# GD32F3x0 register map
File version: 1.0
CPU: CM4 r2p1, little endian, MPU, no FPU, 4 interrupt priority bits
Registers are 32-bit, read-write, reset 0x0 unless marked. A register's access mark holds for its fields unless they carry their own. Offsets are from the block's base; [hi:lo] are bit positions; {n}, {i} and the like mark numbered series.

## EXTI — External interrupt/event controller
Base 0x40010400
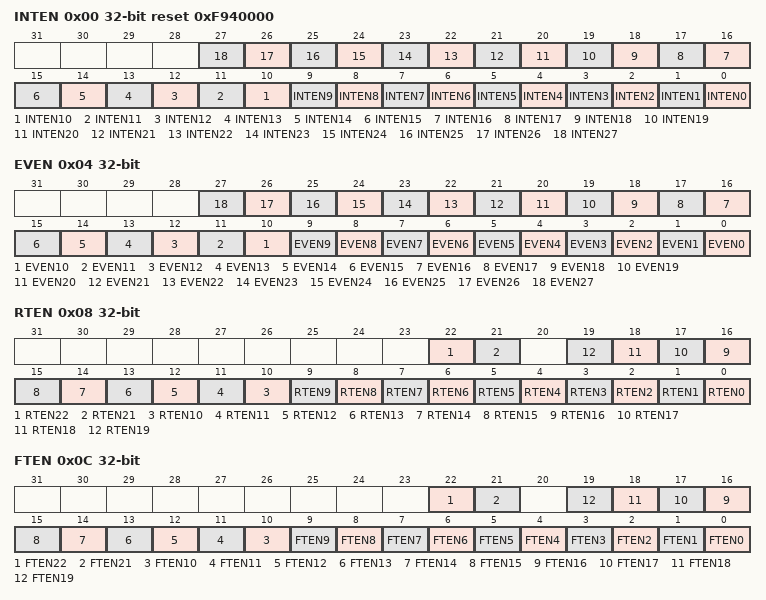
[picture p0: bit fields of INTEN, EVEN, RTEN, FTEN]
0x00 INTEN reset 0xF940000 — Interrupt enable register (EXTI_INTEN)
  [n] INTEN{n} (n=0..27) — Enable Interrupt on line {n}
0x04 EVEN — Event enable register (EXTI_EVEN)
  [n] EVEN{n} (n=0..27) — Enable Event on line {n}
0x08 RTEN — Rising Edge Trigger Enable register (EXTI_RTEN)
  [22] RTEN22 — Rising trigger event configuration of line 22
  [21] RTEN21 — Rising trigger event configuration of line 21
  [n] RTEN{n} (n=0..19) — Rising trigger event configuration of line {n}
0x0C FTEN — Falling Egde Trigger Enable register (EXTI_FTEN)
  [22] FTEN22 — Falling trigger event configuration of line 22
  [21] FTEN21 — Falling trigger event configuration of line 21
  [n] FTEN{n} (n=0..19) — Falling trigger event configuration of line {n}
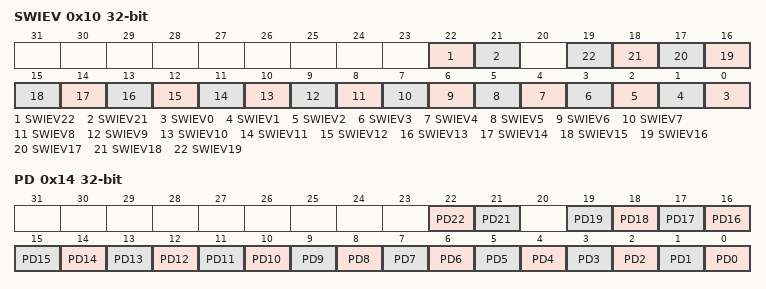
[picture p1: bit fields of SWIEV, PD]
0x10 SWIEV — Software interrupt event register (EXTI_SWIEV)
  [22] SWIEV22 — Software Interrupt on line 22
  [21] SWIEV21 — Software Interrupt on line 21
  [n] SWIEV{n} (n=0..19) — Software Interrupt on line {n}
0x14 PD — Pending register (EXTI_PD)
  [22] PD22 — Pending bit 22
  [21] PD21 — Pending bit 21
  [n] PD{n} (n=0..19) — Pending bit {n}

## FMC
Base 0x40022000
0x00 WS — Wait state register
  [2:0] WSCNT
0x04 KEY wo — Flash unlock key register
  [31:0] KEY — FMC_CTL unlock register
0x08 OBKEY wo — Flash option byte unlock key register
  [31:0] OBKEY — Option byte key
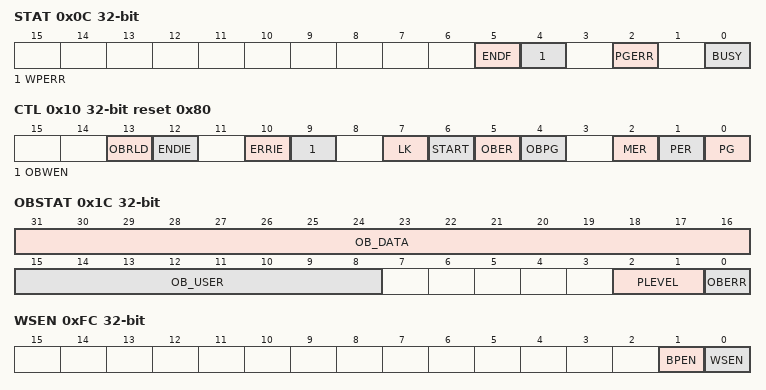
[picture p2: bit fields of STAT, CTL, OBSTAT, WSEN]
0x0C STAT access per field — Flash status register
  [5] ENDF rw — End of operation flag bit
  [4] WPERR rw — Erase/Program protection error flag bit
  [2] PGERR rw — Program error flag bit
  [0] BUSY ro
0x10 CTL reset 0x80 — Flash control register
  [13] OBRLD — Option byte reload bit
  [12] ENDIE — End of operation interrupt enable
  [10] ERRIE — Error interrupt enable
  [9] OBWEN — Option bytes write enable
  [7] LK — Lock
  [6] START
  [5] OBER — Option byte erase
  [4] OBPG — Option byte programming
  [2] MER — Main flash mass erase command bit
  [1] PER — Main flash page erase command bit
  [0] PG — Programming
0x14 ADDR — Flash address register
  [31:0] ADDR — Flash command address
0x1C OBSTAT ro — Option byte status register
  [31:16] OB_DATA
  [15:8] OB_USER
  [2:1] PLEVEL
  [0] OBERR — Option byte error
0x20 WP ro — Write protection register
  [15:0] OB_WP — Write protect
0xFC WSEN ro — Flash wait state control register
  [1] BPEN — FMC bit program enable register
  [0] WSEN — FMC wait state enable register
0x100 PID ro — Flash Product ID register
  [31:0] PID — Product reserved ID code register1

## FWDGT — free watchdog timer
Base 0x40003000
0x00 CTL wo — Control register
  [15:0] CMD — Key value
0x04 PSC — Prescaler register
  [2:0] PSC — Prescaler divider
0x08 RLD reset 0xFFF — Reload register
  [11:0] RLD — Watchdog counter reload value
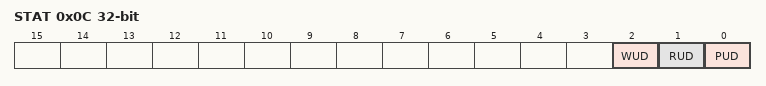
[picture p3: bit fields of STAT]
0x0C STAT ro — Status register
  [2] WUD — Watchdog counter window value update
  [1] RUD — Watchdog counter reload value update
  [0] PUD — Watchdog prescaler value update
0x10 WND ro — Window register
  [11:0] WND — Watchdog counter window value

## GPIOA — General-purpose I/Os
Base 0x48000000
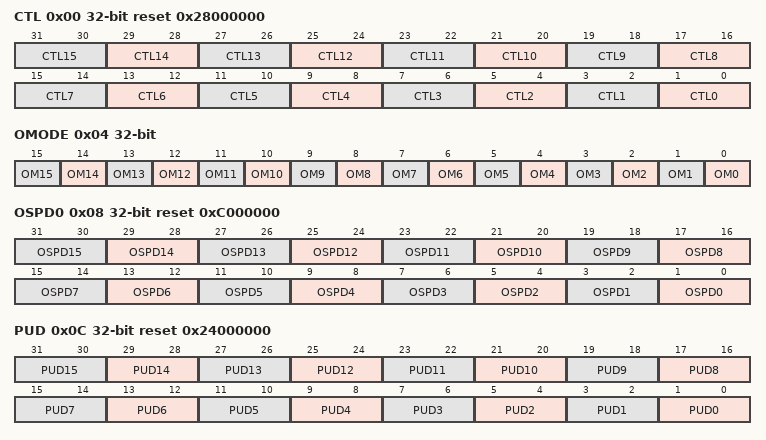
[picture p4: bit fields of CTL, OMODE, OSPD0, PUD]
0x00 CTL reset 0x28000000 — GPIO port control register
  [2n+1:2n] CTL{n} (n=0..15) — Port x configuration bits (y = 0..15)
0x04 OMODE — GPIO port output type register
  [n] OM{n} (n=0..15) — Port x configuration bit {n}
0x08 OSPD0 reset 0xC000000 — GPIO port output speed register 0
  [2n+1:2n] OSPD{n} (n=0..15) — Port x configuration bits (y = 0..15)
0x0C PUD reset 0x24000000 — GPIO port pull-up/pull-down register
  [2n+1:2n] PUD{n} (n=0..15) — Port x configuration bits (y = 0..15)
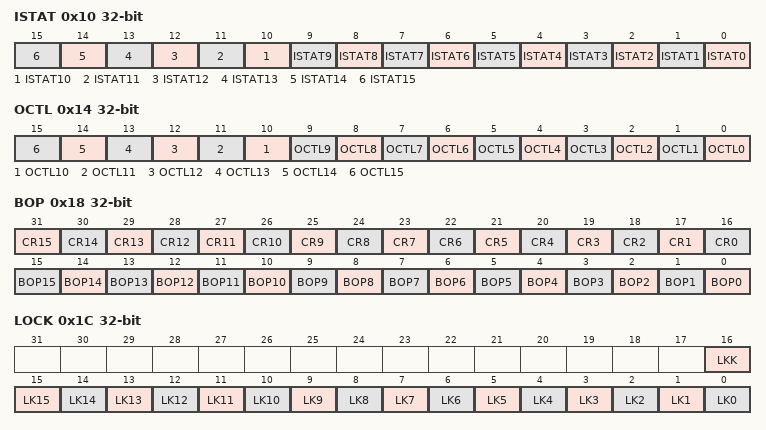
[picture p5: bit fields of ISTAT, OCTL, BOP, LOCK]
0x10 ISTAT ro — GPIO port input data register
  [n] ISTAT{n} (n=0..15) — Port input data (y = 0..15)
0x14 OCTL — GPIO port output data register
  [n] OCTL{n} (n=0..15) — Port output data (y = 0..15)
0x18 BOP wo — GPIO port bit set/reset register
  [n+16] CR{n} (n=1..15) — Port x reset bit y (y = 0..15)
  [16] CR0 — Port x reset bit y (y= 0..15)
  [n] BOP{n} (n=0..15) — Port x set bit y (y= 0..15)
0x1C LOCK — GPIO port configuration lock register
  [16] LKK — Port x lock bit y
  [n] LK{n} (n=0..15) — Port x lock bit y (y= 0..15)
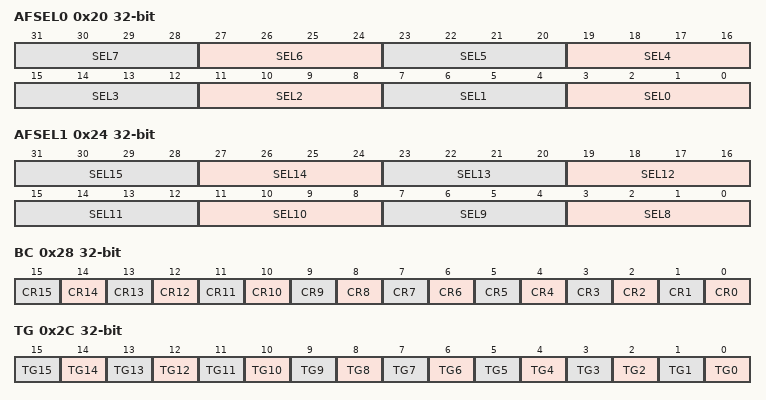
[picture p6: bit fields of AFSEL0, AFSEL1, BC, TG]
0x20 AFSEL0 — GPIO alternate function low register
  [4n+3:4n] SEL{n} (n=0..7) — Alternate function selection for port x bit y (y = 0..7)
0x24 AFSEL1 — GPIO alternate function register 1
  [4n-29:4n-32] SEL{n} (n=8..15) — Alternate function selection for port x bit y (y = 8..15)
0x28 BC wo — Port bit reset register
  [n] CR{n} (n=0..15) — Port cleat bit
0x2C TG wo — Port bit toggle register
  [n] TG{n} (n=0..15) — Port toggle bit
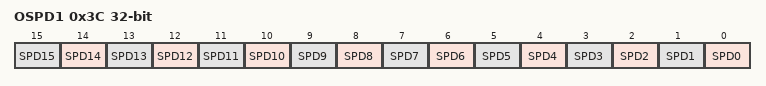
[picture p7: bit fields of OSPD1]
0x3C OSPD1 — Port output speed register 1
  [n] SPD{n} (n=0..15) — Set Very High output speed when OSPDy(y=0..15) is 0b11

## GPIOB — General-purpose I/Os
Base 0x48000400
Registers as GPIOA; these are added or differ:
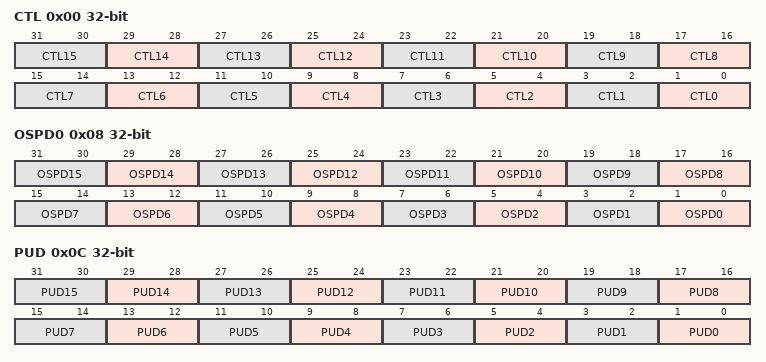
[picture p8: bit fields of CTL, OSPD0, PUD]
0x00 CTL — GPIO port control register
  [2n+1:2n] CTL{n} (n=0..15) — Port x configuration bits (y = 0..15)
0x08 OSPD0 — GPIO port output speed register 0
  [2n+1:2n] OSPD{n} (n=0..15) — Port x configuration bits (y = 0..15)
0x0C PUD — GPIO port pull-up/pull-down register
  [2n+1:2n] PUD{n} (n=0..15) — Port x configuration bits (y = 0..15)

## GPIOC — General-purpose I/Os
Base 0x48000800
Registers as GPIOB, without LOCK.

## GPIOD — General-purpose I/Os
Base 0x48000C00
Registers as GPIOB, without LOCK, AFSEL0, AFSEL1.

## GPIOF — General-purpose I/Os
Base 0x48001400
Registers as GPIOB, without LOCK, AFSEL0, AFSEL1; these are added or differ:
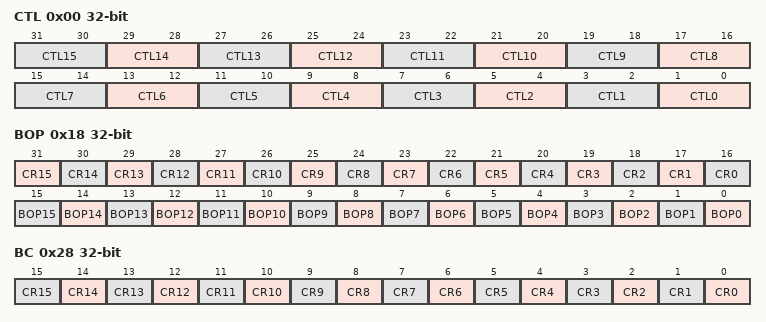
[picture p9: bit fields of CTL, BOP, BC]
0x00 CTL — GPIOF port control register
  [2n+1:2n] CTL{n} (n=0..15) — Port x configuration bits (y = 0..15)
0x18 BOP wo — GPIO port bit set/reset register
  [n+16] CR{n} (n=1..15) — Port x reset bit y (y = 0..15)
  [16] CR0 — Port x set bit y (y= 0..15)
  [n] BOP{n} (n=0..15) — Port x set bit y (y= 0..15)
0x28 BC wo — Port bit reset register
  [n] CR{n} (n=0..15) — Port x Reset bit y
